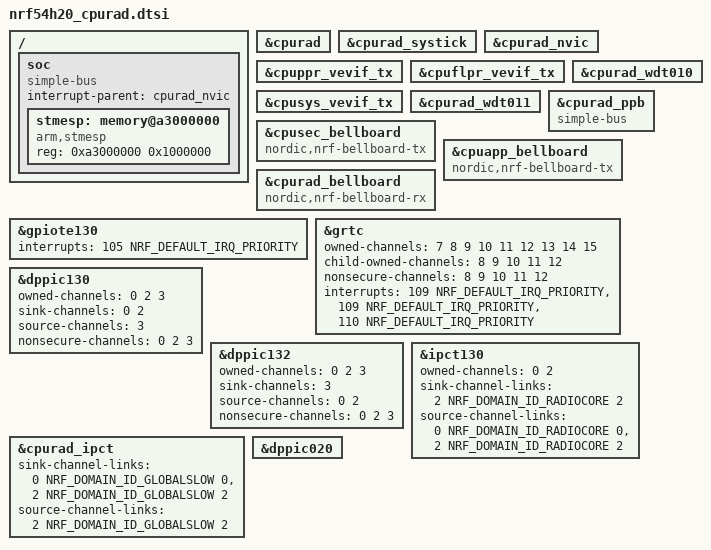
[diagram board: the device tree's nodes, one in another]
/*
 * Copyright (c) 2024 Nordic Semiconductor ASA
 *
 * SPDX-License-Identifier: Apache-2.0
 */

#include <nordic/nrf54h20.dtsi>

cpu: &cpurad {};
systick: &cpurad_systick {};
nvic: &cpurad_nvic {};
cpuppr_vevif: &cpuppr_vevif_tx {};
cpuflpr_vevif: &cpuflpr_vevif_tx {};
cpusys_vevif: &cpusys_vevif_tx {};
wdt010: &cpurad_wdt010 {};
wdt011: &cpurad_wdt011 {};

/delete-node/ &cpuapp;
/delete-node/ &cpuapp_peripherals;
/delete-node/ &cpuapp_ppb;
/delete-node/ &cpuapp_ram0;
/delete-node/ &cpuppr;
/delete-node/ &cpuflpr;

/ {
	soc {
		compatible = "simple-bus";
		interrupt-parent = <&cpurad_nvic>;
		ranges;

		stmesp: memory@a3000000 {
			compatible = "arm,stmesp";
			reg = <0xa3000000 0x1000000>;
		};
	};
};

&cpurad_ppb {
	compatible = "simple-bus";
	ranges;
};

&cpusec_bellboard {
	compatible = "nordic,nrf-bellboard-tx";
};

&cpuapp_bellboard {
	compatible = "nordic,nrf-bellboard-tx";
};

&cpurad_bellboard {
	compatible = "nordic,nrf-bellboard-rx";
};

&gpiote130 {
	interrupts = <105 NRF_DEFAULT_IRQ_PRIORITY>;
};

&grtc {
	owned-channels = <7 8 9 10 11 12 13 14 15>;
	child-owned-channels = <8 9 10 11 12>;
	nonsecure-channels = <8 9 10 11 12>;
	interrupts = <109 NRF_DEFAULT_IRQ_PRIORITY>,
		     <109 NRF_DEFAULT_IRQ_PRIORITY>,
		     <110 NRF_DEFAULT_IRQ_PRIORITY>;
};

&dppic130 {
	owned-channels = <0 2 3>;
	sink-channels = <0 2>;
	source-channels = <3>;
	nonsecure-channels = <0 2 3>;
	status = "okay";
};

&dppic132 {
	owned-channels = <0 2 3>;
	sink-channels = <3>;
	source-channels = <0 2>;
	nonsecure-channels = <0 2 3>;
	status = "okay";
};

&ipct130 {
	status = "okay";
	owned-channels = <0 2>;
	sink-channel-links = <2 NRF_DOMAIN_ID_RADIOCORE 2>;
	source-channel-links = <0 NRF_DOMAIN_ID_RADIOCORE 0>,
			       <2 NRF_DOMAIN_ID_RADIOCORE 2>;
};

&cpurad_ipct {
	status = "okay";
	sink-channel-links = <0 NRF_DOMAIN_ID_GLOBALSLOW 0>,
			     <2 NRF_DOMAIN_ID_GLOBALSLOW 2>;
	source-channel-links = <2 NRF_DOMAIN_ID_GLOBALSLOW 2>;
};

&dppic020 {
	status = "okay";
};
